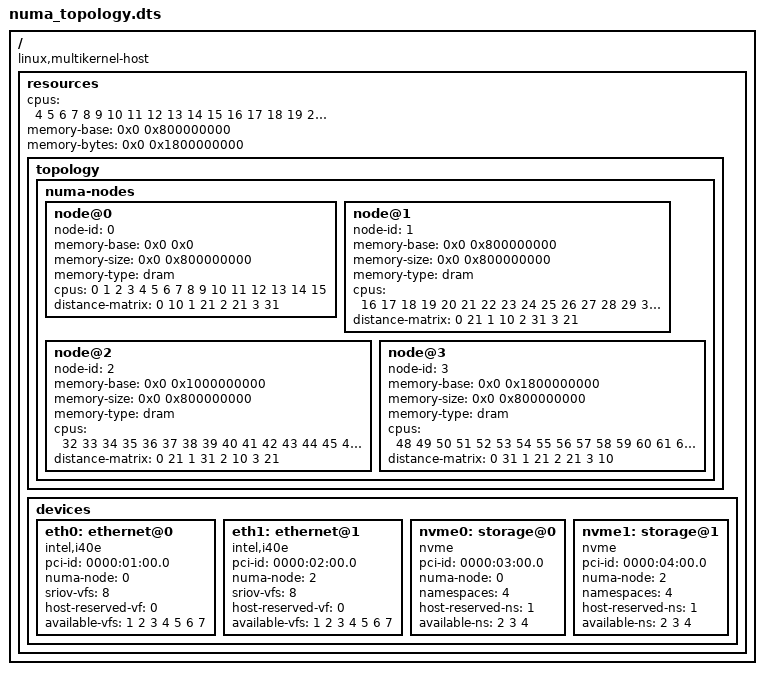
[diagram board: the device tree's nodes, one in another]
/*
 * NUMA Topology Baseline Example
 *
 * Baseline defines hardware resources with NUMA topology information.
 * All CPU values are physical CPU IDs (APIC IDs on x86), not logical
 * CPU numbers.
 *
 * Note: `kerf init --cpus=...` discovers the host topology automatically;
 * a hand-written topology section is only needed for explicit control.
 *
 * The per-node distance-matrix property is a flat list of
 * <target-node distance> pairs.
 *
 * Usage: kerf init --input=numa_topology.dts
 */

/multikernel-v1/;

/ {
    compatible = "linux,multikernel-host";

    resources {
        cpus = <4 5 6 7 8 9 10 11 12 13 14 15 16 17 18 19
                20 21 22 23 24 25 26 27 28 29 30 31 32 33 34 35
                36 37 38 39 40 41 42 43 44 45 46 47 48 49 50 51
                52 53 54 55 56 57 58 59 60 61 62 63>;

        topology {
            numa-nodes {
                node@0 {
                    node-id = <0>;
                    memory-base = <0x0 0x0>;
                    memory-size = <0x0 0x800000000>;  // 32GB
                    memory-type = "dram";
                    cpus = <0 1 2 3 4 5 6 7 8 9 10 11 12 13 14 15>;
                    distance-matrix = <0 10 1 21 2 21 3 31>;
                };

                node@1 {
                    node-id = <1>;
                    memory-base = <0x0 0x800000000>;
                    memory-size = <0x0 0x800000000>;  // 32GB
                    memory-type = "dram";
                    cpus = <16 17 18 19 20 21 22 23 24 25 26 27 28 29 30 31>;
                    distance-matrix = <0 21 1 10 2 31 3 21>;
                };

                node@2 {
                    node-id = <2>;
                    memory-base = <0x0 0x1000000000>;
                    memory-size = <0x0 0x800000000>;  // 32GB
                    memory-type = "dram";
                    cpus = <32 33 34 35 36 37 38 39 40 41 42 43 44 45 46 47>;
                    distance-matrix = <0 21 1 31 2 10 3 21>;
                };

                node@3 {
                    node-id = <3>;
                    memory-base = <0x0 0x1800000000>;
                    memory-size = <0x0 0x800000000>;  // 32GB
                    memory-type = "dram";
                    cpus = <48 49 50 51 52 53 54 55 56 57 58 59 60 61 62 63>;
                    distance-matrix = <0 31 1 21 2 21 3 10>;
                };
            };
        };

        memory-base = <0x0 0x800000000>;
        memory-bytes = <0x0 0x1800000000>;  // 96GB

        devices {
            eth0: ethernet@0 {
                compatible = "intel,i40e";
                pci-id = "0000:01:00.0";
                numa-node = <0>;
                sriov-vfs = <8>;
                host-reserved-vf = <0>;
                available-vfs = <1 2 3 4 5 6 7>;
            };

            eth1: ethernet@1 {
                compatible = "intel,i40e";
                pci-id = "0000:02:00.0";
                numa-node = <2>;
                sriov-vfs = <8>;
                host-reserved-vf = <0>;
                available-vfs = <1 2 3 4 5 6 7>;
            };

            nvme0: storage@0 {
                compatible = "nvme";
                pci-id = "0000:03:00.0";
                numa-node = <0>;
                namespaces = <4>;
                host-reserved-ns = <1>;
                available-ns = <2 3 4>;
            };

            nvme1: storage@1 {
                compatible = "nvme";
                pci-id = "0000:04:00.0";
                numa-node = <2>;
                namespaces = <4>;
                host-reserved-ns = <1>;
                available-ns = <2 3 4>;
            };
        };
    };
};
